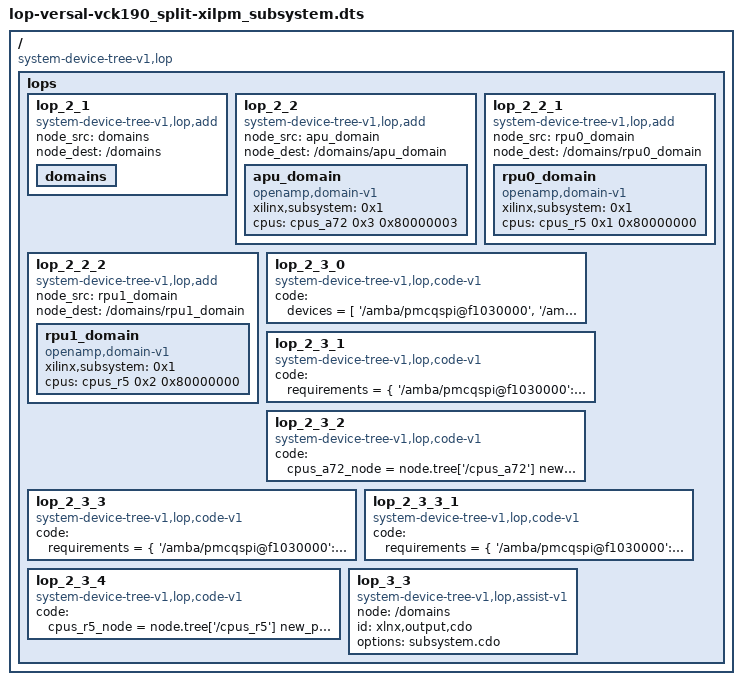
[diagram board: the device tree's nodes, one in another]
/dts-v1/;
/ {
	compatible = "system-device-tree-v1,lop";
	lops {


		lop_2_1 {
			compatible = "system-device-tree-v1,lop,add";
			node_src = "domains";
			node_dest = "/domains";
			domains {
				 #address-cells = <0x2>;
				 #size-cells = <0x2>;
			};
		};
		lop_2_2 {
			compatible = "system-device-tree-v1,lop,add";
			node_src = "apu_domain";
			node_dest = "/domains/apu_domain";
			apu_domain {
				compatible = "openamp,domain-v1";
				xilinx,subsystem = <0x1>;
				#xilinx,config-cells = <2>;
				
				/* cdo add subsystem for apu is inferred as cpus_a72 is in cpu field */
				cpus = <&cpus_a72 0x3 0x80000003>;
			};
		};
		lop_2_2_1 {
			compatible = "system-device-tree-v1,lop,add";
			node_src = "rpu0_domain";
			node_dest = "/domains/rpu0_domain";
			rpu0_domain {
				compatible = "openamp,domain-v1";
				xilinx,subsystem = <0x1>;
				#xilinx,config-cells = <2>;
			
				/* subsystem for split r5-0 */
				cpus = <&cpus_r5 0x1 0x80000000>;
			};
		};
		lop_2_2_2 {
			compatible = "system-device-tree-v1,lop,add";
			node_src = "rpu1_domain";
			node_dest = "/domains/rpu1_domain";
			rpu1_domain {
				compatible = "openamp,domain-v1";
				xilinx,subsystem = <0x1>;
				#xilinx,config-cells = <2>;
			
				/* subsystem for split r5-1 */
				cpus = <&cpus_r5 0x2 0x80000000>;
			};
		};

		lop_2_3_0 {
			compatible = "system-device-tree-v1,lop,code-v1";
			code = "
			devices = [
			'/amba/pmcqspi@f1030000',
			'/amba_pl/ai_engine@40000000',
			'/amba/serial@ff000000', 
			'/amba/serial@ff010000' ,
			'/amba/mailbox@ff330000',
			'/amba/mailbox@ff340000',
			'/amba/mailbox@ff350000',
			'/amba/mailbox@ff360000',
			'/amba/mailbox@ff370000',
			'/amba/mailbox@ff380000',
			'/amba/mailbox@ff3a0000',
			'/memory@fffc0000',
			'/amba/psv_tcm_global@ffe00000',
			'/amba/psv_tcm_global@ffe20000',
			'/amba/psv_tcm_global@ffe90000',
			'/amba/psv_tcm_global@ffeb0000',

			'/cpus_a72/cpu@0',
			'/cpus_a72/cpu@1',

			'/amba/ethernet@ff0c0000',
			'/amba/ethernet@ff0d0000',
			'/amba/sdhci@f1040000'  , 
			'/amba/sdhci@f1050000'   ,

			'/amba/can@ff060000'     ,
			'/amba/can@ff070000'     ,
			'/amba/i2c@ff020000'     ,
			'/amba/i2c@ff030000'     ,
			'/amba/dma@ffaf0000',
			'/amba/dma@ffae0000',
			'/amba/dma@ffad0000',
			'/amba/dma@ffac0000',
			'/amba/dma@ffab0000',
			'/amba/dma@ffaa0000',
			'/amba/dma@ffa90000',
			'/amba/dma@ffa80000',
			'/memory@800000000' ,
			'/amba/rtc@f12a0000',
			'/amba/timer@ff0e0000',
			'/amba/usb@ff9d0000'  ,
			'/amba/watchdog@fd4d0000',
			'/amba/gpio@ff0b0000',
			'/amba/gpio@f1020000',
			'/amba/spi@ff040000',
			'/amba/spi@ff050000',
			'/cpus_r5/cpu@4',
			'/cpus_r5/cpu@5',
			'/amba/timer@ff0f0000',
			'/amba/timer@ff100000',
			]

			# for each device in nodes_to_update:
			# find node in tree with name
			# generate phandle for that node
			root_node = node.tree['/']
			for n in devices:
				target_node = root_node.tree[n]
				new_phandle = root_node.tree.phandle_gen()
				newprop = LopperProp(name='phandle',value=new_phandle)
				target_node.phandle = new_phandle
				target_node + newprop
				target_node.sync(root_node.tree.fdt)
			";
		};

		lop_2_3_1 {
			compatible = "system-device-tree-v1,lop,code-v1";
			code = "
			requirements = {
			'/amba/pmcqspi@f1030000':[0x4,0xfffff],
			'/amba_pl/ai_engine@40000000':[0x4,0xfffff],
			'/amba/serial@ff000000':[0x5,0x38],
			'/amba/serial@ff010000':[0x7,0x38],
			'/amba/mailbox@ff330000':[0x8104,0xfffff],
			'/amba/mailbox@ff340000':[0x4,0xfffff],
			'/amba/mailbox@ff350000':[0x4,0xfffff],
			'/amba/mailbox@ff360000':[0x4,0xfffff],
			'/amba/mailbox@ff370000':[0x4,0xfffff],
			'/amba/mailbox@ff380000':[0x4,0xfffff],
			'/amba/mailbox@ff3a0000':[0x4,0xfffff],
			'/memory@fffc0000':[0x8304,0xfffff],
			'/amba/psv_tcm_global@ffe00000':[0x4,0xfffff],
			'/amba/psv_tcm_global@ffe20000':[0x4,0xfffff],
			'/amba/psv_tcm_global@ffe90000':[0x4,0xfffff],
			'/amba/psv_tcm_global@ffeb0000':[0x4,0xfffff],

			'/cpus_a72/cpu@0':[0x8104,0xfffff],
			'/cpus_a72/cpu@1':[0x8104,0xfffff],

			'/amba/ethernet@ff0c0000':[0x8706,0x38],
			'/amba/ethernet@ff0d0000':[0x8706,0x38],
			'/amba/sdhci@f1040000':[0x7,0x38],
			'/amba/sdhci@f1050000':[0x7,0xfffff],

			'/amba/can@ff060000':[0x4,0xfffff],
			'/amba/can@ff070000':[0x4,0xfffff],
			'/amba/i2c@ff020000':[0x4,0xfffff],
			'/amba/i2c@ff030000':[0x4,0xfffff],
			'/amba/dma@ffaf0000':[0x4,0xfffff],
			'/amba/dma@ffae0000':[0x4,0xfffff],
			'/amba/dma@ffad0000':[0x4,0xfffff],
			'/amba/dma@ffac0000':[0x4,0xfffff],
			'/amba/dma@ffab0000':[0x4,0xfffff],
			'/amba/dma@ffaa0000':[0x4,0xfffff],
			'/amba/dma@ffa90000':[0x4,0xfffff],
			'/amba/dma@ffa80000':[0x4,0xfffff],
			'/memory@800000000':[0x7,0x38],
			'/amba/rtc@f12a0000':[0x4,0xfffff],
			'/amba/timer@ff0e0000':[0x4,0xfffff],
			'/amba/usb@ff9d0000':[0x7,0x38],
			'/amba/watchdog@fd4d0000':[0x7,0x38],
			'/amba/gpio@ff0b0000':[0x4,0xfffff],
			'/amba/gpio@f1020000':[0x4,0xfffff],
			'/amba/spi@ff040000':[0x4,0xfffff],
			'/amba/spi@ff050000':[0x4,0xfffff],
			}

			device_list = []

			# set device list for apu domain
			apu_domain_node = node.tree['/domains/apu_domain']
		
			# for each device in nodes_to_update:
			# find node in tree with name
			# generate phandle for that node
			# add to prop the following: 'phandle nodes_to_update[info]'
			for n in requirements.keys():
				target_node = apu_domain_node.tree[n]
				device_list.append(target_node.propval('phandle'))
				device_list.append(requirements[n][0])
				device_list.append(requirements[n][1])

			device_list_prop = LopperProp(name='xilinx,subsystem-config',value=device_list)

			apu_domain_node + device_list_prop
			apu_domain_node.sync( apu_domain_node.tree.fdt )
			";
		};

		lop_2_3_2 {
			compatible = "system-device-tree-v1,lop,code-v1";
			code = "
			cpus_a72_node = node.tree['/cpus_a72']
			new_phandle = cpus_a72_node.tree.phandle_gen()
			newprop = LopperProp(name='phandle',value=new_phandle)
			cpus_a72_node.phandle = new_phandle
			cpus_a72_node + newprop
			cpus_a72_node.sync( cpus_a72_node.tree.fdt )

			# set cpus to reference the new phandle
			apu_domain_node = node.tree['/domains/apu_domain']
			apu_domain_node_cpus = apu_domain_node.propval('cpus')
			apu_domain_node_cpus[0] = new_phandle
			apu_domain_node['cpus'].value = apu_domain_node_cpus
			";
                };
		lop_2_3_3 {
			compatible = "system-device-tree-v1,lop,code-v1";
			code = "
			requirements = {
			'/amba/pmcqspi@f1030000':[0x4,0xfffff],
			'/amba/serial@ff000000':[0x5,0x38],
			'/amba/serial@ff010000':[0x7,0x38],
			'/amba/mailbox@ff330000':[0x4,0xfffff],
			'/amba/mailbox@ff340000':[0x8104,0xfffff],
			'/amba/mailbox@ff350000':[0x4,0xfffff],
			'/amba/mailbox@ff360000':[0x4,0xfffff],
			'/amba/mailbox@ff370000':[0x4,0xfffff],
			'/amba/mailbox@ff380000':[0x4,0xfffff],
			'/amba/mailbox@ff3a0000':[0x4,0xfffff],
			'/amba/timer@ff0f0000':[0x7,0x1],
			'/amba/serial@ff010000':[ 0x8707, 0x2],
			'/amba/watchdog@fd4d0000':[ 0x7, 0x2],
			'/amba/psv_tcm_global@ffe00000':[0x8304,0xfffff],
			'/amba/psv_tcm_global@ffe20000':[0x8304,0xfffff],
			'/amba/rtc@f12a0000':[ 0x4, 0xfffff],
			'/cpus_r5/cpu@4':[ 0x8104, 0xfffff],
			}

			device_list = []

			# set device list for apu domain
			rpu0_domain_node = node.tree['/domains/rpu0_domain']
		
			# for each device in nodes_to_update:
			# find node in tree with name
			# generate phandle for that node
			# add to prop the following: 'phandle nodes_to_update[info]'
			for n in requirements.keys():
				target_node = rpu0_domain_node.tree[n]
				device_list.append(target_node.phandle)
				device_list.append(requirements[n][0])
				device_list.append(requirements[n][1])

			device_list_prop = LopperProp(name='xilinx,subsystem-config',value=device_list)

			rpu0_domain_node + device_list_prop
			rpu0_domain_node.sync( rpu0_domain_node.tree.fdt )
			";
		};
		lop_2_3_3_1 {
			compatible = "system-device-tree-v1,lop,code-v1";
			code = "
			requirements = {
			'/amba/pmcqspi@f1030000':[0x4,0xfffff],
			'/amba/serial@ff000000':[0x5,0x38],
			'/amba/mailbox@ff330000':[0x4,0xfffff],
			'/amba/mailbox@ff340000':[0x4,0xfffff],
			'/amba/mailbox@ff350000':[0x8104,0xfffff],
			'/amba/mailbox@ff360000':[0x4,0xfffff],
			'/amba/mailbox@ff370000':[0x4,0xfffff],
			'/amba/mailbox@ff380000':[0x4,0xfffff],
			'/amba/mailbox@ff3a0000':[0x4,0xfffff],
			'/amba/timer@ff100000':[0x7,0x1],
			'/amba/serial@ff010000':[ 0x8707, 0x4],
			'/amba/watchdog@fd4d0000':[ 0x7, 0x4],
			'/amba/psv_tcm_global@ffe90000':[0x8304,0xfffff],
			'/amba/psv_tcm_global@ffeb0000':[0x8304,0xfffff],
			'/amba/rtc@f12a0000':[ 0x4, 0xfffff],
			'/cpus_r5/cpu@5':[ 0x8104, 0xfffff],
			}

			device_list = []

			# set device list for apu domain
			rpu1_domain_node = node.tree['/domains/rpu1_domain']
		
			# for each device in nodes_to_update:
			# find node in tree with name
			# generate phandle for that node
			# add to prop the following: 'phandle nodes_to_update[info]'
			for n in requirements.keys():
				target_node = rpu1_domain_node.tree[n]
				device_list.append(target_node.phandle)
				device_list.append(requirements[n][0])
				device_list.append(requirements[n][1])

			device_list_prop = LopperProp(name='xilinx,subsystem-config',value=device_list)

			rpu1_domain_node + device_list_prop
			rpu1_domain_node.sync( rpu1_domain_node.tree.fdt )
			";
		};

		lop_2_3_4 {
			compatible = "system-device-tree-v1,lop,code-v1";
			code = "
			cpus_r5_node = node.tree['/cpus_r5']
			new_phandle = cpus_r5_node.tree.phandle_gen()
			newprop = LopperProp(name='phandle',value=new_phandle)
			cpus_r5_node.phandle = new_phandle
			cpus_r5_node + newprop
			cpus_r5_node.sync( cpus_r5_node.tree.fdt )

			# set cpus to reference the new phandle
			rpu0_domain_node = node.tree['/domains/rpu0_domain']
			rpu0_domain_node_cpus = rpu0_domain_node.propval('cpus')
			rpu0_domain_node_cpus[0] = new_phandle
			rpu0_domain_node['cpus'].value = rpu0_domain_node_cpus

			# set cpus to reference the new phandle
			rpu1_domain_node = node.tree['/domains/rpu1_domain']
			rpu1_domain_node_cpus = rpu1_domain_node.propval('cpus')
			rpu1_domain_node_cpus[0] = new_phandle
			rpu1_domain_node['cpus'].value = rpu1_domain_node_cpus
			";
                };
		lop_3_3 {
			compatible = "system-device-tree-v1,lop,assist-v1";
			node = "/domains";
			id = "xlnx,output,cdo";
			options = "subsystem.cdo";
		};
	};

};
